# uart_reva_me10 register map
Registers are 32-bit, access not given, no defined reset value unless marked. A register's access mark holds for its fields unless they carry their own. Offsets are from the block's base; lines under a group give offsets from that group; [hi:lo] are bit positions; {n}, {i} and the like mark numbered series; 'fields as' and 'values as' point back to an identical list; <NAME> marks a mode.

## Memory map
0x40042000 UART0 size 0x1000 — UART

## Interrupts
14 UART0 — UART0 IRQ

## UART0 — UART
Base 0x40042000
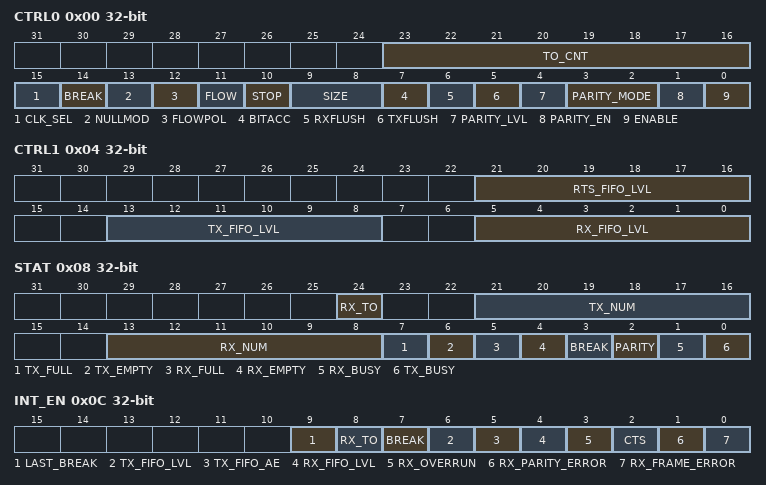
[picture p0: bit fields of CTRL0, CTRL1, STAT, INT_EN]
0x00 CTRL0 — Control Register.
  [23:16] TO_CNT — RX Time Out. RX time out interrupt will occur after TO_CNT Uart characters if RX-FIFO is not empty and RX FIFO has not been read.
  [15] CLK_SEL — Baud Rate Clock Source Select. Selects the baud rate clock.
    0=periph_clk (System clock.); 1=alt_clk (Alternate 7.3727MHz internal clock. Useful in low power modes when the system clock is slow.)
  [14] BREAK — Break control bit. It causes a break condition to be transmitted to receiving UART.
    0=normal (Break characters are not generated.); 1=Break characters are sent (all the bits are at '0' including start/parity/stop)
  [13] NULLMOD — NULL Modem Support (RTS/CTS and TXD/RXD swap).
    0=normal (Direct convention.); 1=swapped (Null Modem Mode. RTS/CTS swapped and TX/RX swapped.)
  [12] FLOWPOL — RTS/CTS polarity.
    0=active_low (RTS/CTS asserted is logic 0.); 1=active_high (RTS/CTS asserted is logic 1.)
  [11] FLOW — Enables/disables hardware flow control.
    0=dis (HW Flow Control disabled); 1=en (HW Flow Control with RTS/CTS enabled)
  [10] STOP — Selects the number of stop bits that will be generated.
    0=1_stopbits; 1=2_stopbits (1.5 stop bits if the character size is 5, 2 stop bits for all other character sizes.)
  [9:8] SIZE — Selects UART character size.
    {v}={v+5}bit_data ({v+5} bits.) (v=0..3)
  [7] BITACC — If set, bit accuracy is selected, in this case the bit duration is the same for all the bits with the optimal accuracy. But the frame duration can have a significant deviation from the expected baudrate.If clear, frame accuracy is selected, therefore bits can have different duration in order to guarantee the minimum frame deviation.
    0=Frame accuracy; 1=bit (Bit accuracy.)
  [6] RXFLUSH — Flushes the RX FIFO buffer.
    0=nop (No flush operation in progress/no effect.); 1=flush (RX FIFO flush initiation or flush operation currently in progress.)
  [5] TXFLUSH — Flushes the TX FIFO buffer.
    0=nop (No flush operation in progress/no effect.); 1=flush (TX FIFO flush initiation or flush operation currently in progress.)
  [4] PARITY_LVL — Selects parity based on 1s or 0s count (when PARITY_EN=1).
    0=ZERO (Parity calculation is based on number of 0s in frame.); 1=ONE (Parity calculation is based on number of 1s in frame.)
  [3:2] PARITY_MODE — When PARITY_EN=1, selects odd, even, Mark or Space parity. Mark parity = always 1; Space parity = always 0.
    0=Even parity selected; 1=odd (Odd parity selected.); 2=Mark parity selected; 3=Space parity selected
  [1] PARITY_EN — Enable/disable Parity bit (9th character).
    0=dis (No Parity); 1=en (Parity enabled as 9th bit)
  [0] ENABLE — UART enabled, to enable UART block, it is used to drive a gated clock in order to save power consumption when UART is not used. FIFOs are flushed when UART is disabled.
    0=dis (UART disabled. FIFOs are flushed. Clock is gated off for power savings.); 1=en (UART enabled.)
0x04 CTRL1 — Threshold Control register.
  [21:16] RTS_FIFO_LVL — RTS threshold control. When the RX FIFO reaches this many bytes or higher, the RTS output signal is deasserted, informing the transmitting UART to stop sending data to this UART.
  [13:8] TX_FIFO_LVL — TX FIFO Threshold Level. When the TX FIFO reaches this many bytes or higher, UARTn_INTFL.tx_fifo_level is set.
  [5:0] RX_FIFO_LVL — RX FIFO Threshold Level.When the RX FIFO reaches this many bytes or higher, UARTn_INFTL.rx_fifo_level is set.
0x08 STAT ro — Status Register.
  [24] RX_TO — Receiver Timeout Status. Indicates if timeout has occurred.
    1=expired (RX timeout has occurred.)
  [21:16] TX_NUM — Indicates the number of bytes currently in the TX FIFO.
  [13:8] RX_NUM — Indicates the number of bytes currently in the RX FIFO.
  [7] TX_FULL — Read-only flag indicating the TX FIFO state.
    1=full (TX FIFO empty.)
  [6] TX_EMPTY — Read-only flag indicating the TX FIFO state.
    1=empty (TX FIFO empty.)
  [5] RX_FULL — Read-only flag indicating the RX FIFO state.
    1=full (RX FIFO full.)
  [4] RX_EMPTY — Read-only flag indicating the RX FIFO state.
    1=empty (RX FIFO empty.)
  [3] BREAK — Received BREAK status. BREAKS is cleared when UART_STAT register is read. Received data input is held in spacing (logic 0) state for longer than a full word transmission time (that is, the total time of Start bit + data bits + Parity + Stop bits).
    1=recv (Break frame received.)
  [2] PARITY — 9th Received bit state. This bit identifies the state of the 9th bit of received data. Only available for UART_CTRL.SIZE[1:0]=3.
    0=Received a parity bit of 0; 1=Received a parity bit of 1
  [1] RX_BUSY — Read-only flag indicating the UARTreceiver status.
    0=idle (The UART block is not currently receiving chracters.); 1=busy (UART block currently receiving chracters.)
  [0] TX_BUSY — Read-only flag indicating the UART transmit status.
    0=idle (The UART block is not currently transmitting chracters.); 1=busy (UART block currently transmitting chracters.)
0x0C INT_EN — Interrupt Enable Register.
  [9] LAST_BREAK — Enable for Last break character interrupt.
    0=dis (Last break frame received interrupt disabled.); 1=en (Last break frame received interrupt enabled.)
  [8] RX_TO — Enable for RX Timeout Interrupt. Trigger if there is no RX communication during n UART characters (n=UART_CN.RXTO).
    0=dis (RX Timeout interrupt disabled.); 1=en (RX Timeout interrupt enabled.)
  [7] BREAK — Enable for received BREAK character interrupt.
    0=dis (Break character received interrupt disabled.); 1=en (Break character received interrupt enabled.)
  [6] TX_FIFO_LVL — Enable for interrupt when TX FIFO reaches the number of bytes configured by the TXTHD field.
    0=dis (TX FIFO Threshold Level interrupt disabled.); 1=en (TX FIFO Threshold Level interrupt enabled.)
  [5] TX_FIFO_AE — Enable for interrupt when TX FIFO has only one byte remaining.
    0=dis (TX FIFO One byte remaining (almost empty) interrupt disabled.); 1=en (TX FIFO one byte remaining (almost empty) interrupt enabled.)
  [4] RX_FIFO_LVL — Enable for interrupt when RX FIFO reaches the number of bytes configured by the RXTHD field.
    0=dis (RX FIFO Threshold Level interrupt disabled.); 1=en (RX FIFO Threshold Level interrupt enabled.)
  [3] RX_OVERRUN — Enable for RX FIFO OVerrun interrupt.
    0=dis (RX Overrun interrupt disabled.); 1=en (RX Overrun interrupt enabled.)
  [2] CTS — Enable for CTS signal change interrupt.
    0=dis (CTS State Change interrupt disabled.); 1=en (CTS State Change interrupt enabled.)
  [1] RX_PARITY_ERROR — Enable for RX Parity Error interrupt.
    0=dis (RX Parity error interrupt disabled.); 1=en (RX Parity error interrupt enabled.)
  [0] RX_FRAME_ERROR — Enable for RX Frame Error Interrupt.
    0=dis (RX Frame error interrupt disabled.); 1=en (RX Frame error interrupt enabled.)
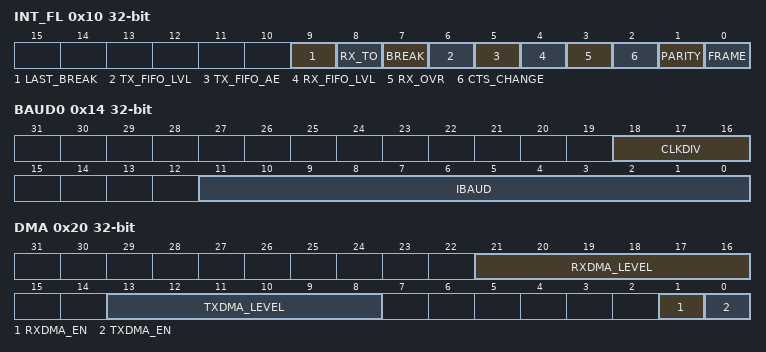
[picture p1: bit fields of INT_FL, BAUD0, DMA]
0x10 INT_FL write-1-clears — Interrupt Status Flags.
  [9] LAST_BREAK — FLAG for Last break character interrupt.
    1=active (Last break character received interrupt active.)
  [8] RX_TO — FLAG for RX Timeout Interrupt. Trigger if there is no RX communication during n UART characters (n=UART_CN.RXTO).
    1=active (Receive timeout expired interrupt active.)
  [7] BREAK — FLAG for received BREAK character interrupt.
    1=active (Break character received interrupt active.)
  [6] TX_FIFO_LVL — FLAG for interrupt when TX FIFO reaches the number of bytes configured by the TXTHD field.
    1=active (TX FIFO threshold level interrupt active.)
  [5] TX_FIFO_AE — FLAG for interrupt when TX FIFO has only one byte remaining.
    1=active (TX FIFO one byte remaining interrupt active.)
  [4] RX_FIFO_LVL — FLAG for interrupt when RX FIFO reaches the number of bytes configured by the RXTHD field.
    1=active (RX FIFO Threshold level interrupt active.)
  [3] RX_OVR — FLAG for RX FIFO Overrun interrupt.
    1=active (RX Overrun interrupt active.)
  [2] CTS_CHANGE — FLAG for CTS signal change interrupt.
    1=active (CTS State change interrupt active.)
  [1] PARITY — FLAG for RX Parity Error interrupt.
    1=active (Receive parity error interrupt active.)
  [0] FRAME — FLAG for RX Frame Error Interrupt.
    1=active (Frame Error interrupt active.)
0x14 BAUD0 — Baud rate register. Integer portion.
  [18:16] CLKDIV — FACTOR must be chosen to have IDIV> 0. factor used in calculation = 128 > > FACTOR.
    0=div128 (Baud Factor 128); 1=div64 (Baud Factor 64); 2=div32 (Baud Factor 32); 3=div16 (Baud Factor 16); 4=div8 (Baud Factor 8)
  [11:0] IBAUD — Integer portion of baud rate divisor value. IBAUD = InputClock / (factor * Baud Rate Frequency).
0x18 BAUD1 — Baud rate register. Decimal Setting.
  [6:0] DBAUD — Decimal portion of baud rate divisor value. DIV = InputClock/ (factor*Baud Rate Frequency). DDIV= (DIV-IDIV) *128.
0x1C FIFO — FIFO Data buffer.
  [7:0] FIFO — Load/unload location for TX and RX FIFO buffers.
0x20 DMA — DMA Configuration.
  [21:16] RXDMA_LEVEL — RX threshold for DMA transmission.
  [13:8] TXDMA_LEVEL — TX threshold for DMA transmission.
  [1] RXDMA_EN — RX DMA channel enable.
    0=dis (DMA is disabled); 1=en (DMA is enabled)
  [0] TXDMA_EN — TX DMA channel enable.
    0=dis (DMA is disabled); 1=en (DMA is enabled)
0x24 TXFIFO — Transmit FIFO Status register.
  [6:0] DATA — Reading from this field returns the next character available at the output of the TX FIFO (if one is available, otherwise 00h is returned).
